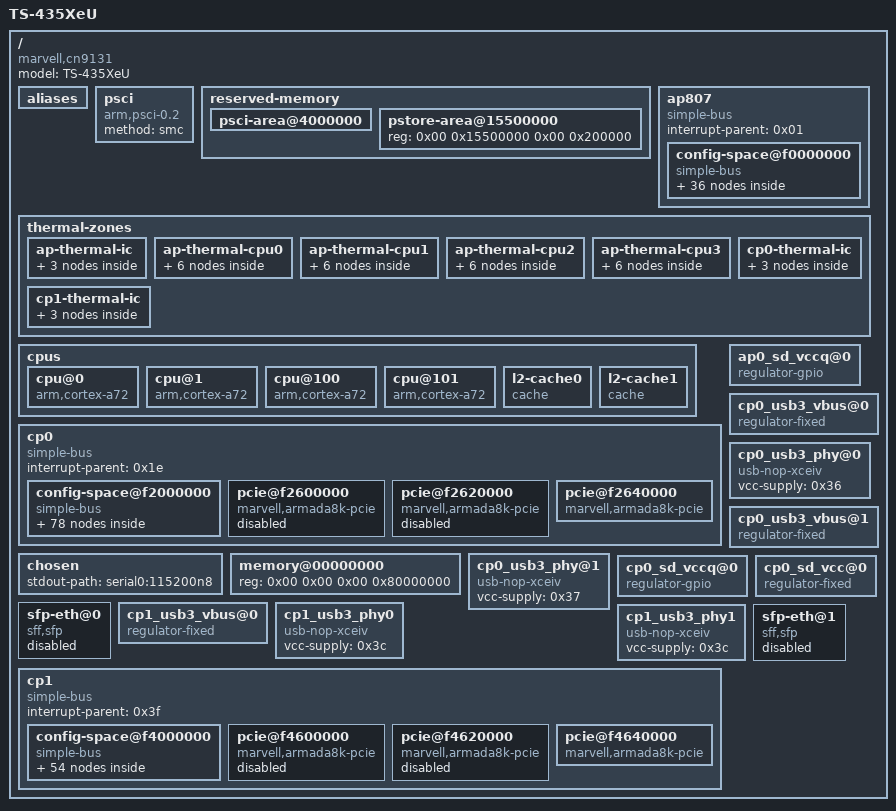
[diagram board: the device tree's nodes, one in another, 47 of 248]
/dts-v1/;

/ {
	#address-cells = <0x02>;
	#size-cells = <0x02>;
	model = "TS-435XeU";
	compatible = "marvell,cn9131\0marvell,cn9130\0marvell,armada-ap807-quad\0marvell,armada-ap807";

	aliases {
		serial0 = "/ap807/config-space@f0000000/serial@512000";
		serial1 = "/ap807/config-space@f0000000/serial@512100";
		gpio0 = "/ap807/config-space@f0000000/system-controller@6f4000/gpio@1040";
		spi0 = "/ap807/config-space@f0000000/spi@510600";
		i2c0 = "/cp0/config-space@f2000000/i2c@701000";
		ethernet0 = "/cp0/config-space@f2000000/ethernet@0/eth0";
		ethernet1 = "/cp0/config-space@f2000000/ethernet@0/eth1";
		ethernet2 = "/cp0/config-space@f2000000/ethernet@0/eth2";
		gpio1 = "/cp0/config-space@f2000000/system-controller@440000/gpio@100";
		gpio2 = "/cp0/config-space@f2000000/system-controller@440000/gpio@140";
		ethernet3 = "/cp1/config-space@f4000000/ethernet@0/eth0";
		gpio3 = "/cp1/config-space@f4000000/system-controller@440000/gpio@100";
		gpio4 = "/cp1/config-space@f4000000/system-controller@440000/gpio@140";
	};

	psci {
		compatible = "arm,psci-0.2";
		method = "smc";
	};

	reserved-memory {
		#address-cells = <0x02>;
		#size-cells = <0x02>;
		ranges;

		psci-area@4000000 {
			reg = <0x00 0x4000000 0x00 0x200000>;
			no-map;
		};

		pstore-area@15500000 {
			reg = <0x00 0x15500000 0x00 0x200000>;
		};
	};

	ap807 {
		#address-cells = <0x02>;
		#size-cells = <0x02>;
		compatible = "simple-bus";
		interrupt-parent = <0x01>;
		ranges;

		config-space@f0000000 {
			#address-cells = <0x01>;
			#size-cells = <0x01>;
			compatible = "simple-bus";
			ranges = <0x00 0x00 0xf0000000 0x1000000>;

			iommu@5000000 {
				compatible = "marvell,ap806-smmu-500\0arm,mmu-500";
				reg = <0x100000 0x100000>;
				dma-coherent;
				#iommu-cells = <0x01>;
				#global-interrupts = <0x01>;
				interrupts = <0x00 0x06 0x04 0x00 0x06 0x04 0x00 0x06 0x04 0x00 0x06 0x04 0x00 0x06 0x04 0x00 0x06 0x04 0x00 0x06 0x04 0x00 0x06 0x04 0x00 0x06 0x04>;
				status = "disabled";
				phandle = <0x05>;
			};

			interrupt-controller@210000 {
				compatible = "arm,gic-400";
				#interrupt-cells = <0x03>;
				#address-cells = <0x01>;
				#size-cells = <0x01>;
				ranges;
				interrupt-controller;
				interrupts = <0x01 0x09 0xf04>;
				reg = <0x210000 0x10000 0x220000 0x20000 0x240000 0x20000 0x260000 0x20000>;
				phandle = <0x01>;

				v2m@280000 {
					compatible = "arm,gic-v2m-frame";
					msi-controller;
					reg = <0x280000 0x1000>;
					arm,msi-base-spi = <0xa0>;
					arm,msi-num-spis = <0x20>;
					phandle = <0x03>;
				};

				v2m@290000 {
					compatible = "arm,gic-v2m-frame";
					msi-controller;
					reg = <0x290000 0x1000>;
					arm,msi-base-spi = <0xc0>;
					arm,msi-num-spis = <0x20>;
				};

				v2m@2a0000 {
					compatible = "arm,gic-v2m-frame";
					msi-controller;
					reg = <0x2a0000 0x1000>;
					arm,msi-base-spi = <0xe0>;
					arm,msi-num-spis = <0x20>;
				};

				v2m@2b0000 {
					compatible = "arm,gic-v2m-frame";
					msi-controller;
					reg = <0x2b0000 0x1000>;
					arm,msi-base-spi = <0x100>;
					arm,msi-num-spis = <0x20>;
				};
			};

			timer {
				compatible = "arm,armv8-timer";
				interrupts = <0x01 0x0d 0xf08 0x01 0x0e 0xf08 0x01 0x0b 0xf08 0x01 0x0a 0xf08>;
			};

			pmu {
				compatible = "arm,cortex-a72-pmu";
				interrupt-parent = <0x02>;
				interrupts = <0x11>;
			};

			odmi@300000 {
				compatible = "marvell,odmi-controller";
				interrupt-controller;
				msi-controller;
				marvell,odmi-frames = <0x04>;
				reg = <0x300000 0x4000 0x304000 0x4000 0x308000 0x4000 0x30c000 0x4000>;
				marvell,spi-base = <0x80 0x88 0x90 0x98>;
			};

			gicp@3f0040 {
				compatible = "marvell,ap806-gicp";
				reg = <0x3f0040 0x10>;
				marvell,spi-ranges = <0x40 0x40 0x120 0x40>;
				msi-controller;
				phandle = <0x2a>;
			};

			interrupt-controller@3f0100 {
				compatible = "marvell,armada-8k-pic";
				reg = <0x3f0100 0x10>;
				#interrupt-cells = <0x01>;
				interrupt-controller;
				interrupts = <0x01 0x0f 0x04>;
				phandle = <0x02>;
			};

			interrupt-controller@3f0200 {
				compatible = "marvell,ap806-sei";
				reg = <0x3f0200 0x40>;
				interrupts = <0x00 0x00 0x04>;
				#interrupt-cells = <0x01>;
				interrupt-controller;
				msi-controller;
				phandle = <0x0b>;
			};

			xor@400000 {
				compatible = "marvell,armada-7k-xor\0marvell,xor-v2";
				reg = <0x400000 0x1000 0x410000 0x1000>;
				msi-parent = <0x03>;
				clocks = <0x04 0x03>;
				dma-coherent;
				iommus = <0x05 0x01>;
				phandle = <0x06>;
			};

			xor@420000 {
				compatible = "marvell,armada-7k-xor\0marvell,xor-v2";
				reg = <0x420000 0x1000 0x430000 0x1000>;
				msi-parent = <0x03>;
				clocks = <0x04 0x03>;
				dma-coherent;
				iommus = <0x05 0x02>;
				phandle = <0x07>;
			};

			xor@440000 {
				compatible = "marvell,armada-7k-xor\0marvell,xor-v2";
				reg = <0x440000 0x1000 0x450000 0x1000>;
				msi-parent = <0x03>;
				clocks = <0x04 0x03>;
				dma-coherent;
				phandle = <0x08>;
			};

			xor@460000 {
				compatible = "marvell,armada-7k-xor\0marvell,xor-v2";
				reg = <0x460000 0x1000 0x470000 0x1000>;
				msi-parent = <0x03>;
				clocks = <0x04 0x03>;
				dma-coherent;
				phandle = <0x09>;
			};

			uio_xor0 {
				compatible = "marvell,uio-xor-v2";
				xor_access = <0x06>;
			};

			uio_xor1 {
				compatible = "marvell,uio-xor-v2";
				xor_access = <0x07>;
			};

			uio_xor2 {
				compatible = "marvell,uio-xor-v2";
				xor_access = <0x08>;
			};

			uio_xor3 {
				compatible = "marvell,uio-xor-v2";
				xor_access = <0x09>;
			};

			spi@510600 {
				compatible = "marvell,armada-380-spi";
				reg = <0x510600 0x50>;
				#address-cells = <0x01>;
				#size-cells = <0x00>;
				interrupts = <0x00 0x15 0x04>;
				clocks = <0x04 0x03>;
				status = "disabled";
			};

			i2c@511000 {
				compatible = "marvell,mv78230-i2c";
				reg = <0x511000 0x20>;
				#address-cells = <0x01>;
				#size-cells = <0x00>;
				interrupts = <0x00 0x14 0x04>;
				clocks = <0x04 0x03>;
				status = "disabled";
			};

			serial@512000 {
				compatible = "snps,dw-apb-uart";
				reg = <0x512000 0x100>;
				reg-shift = <0x02>;
				interrupts = <0x00 0x13 0x04>;
				reg-io-width = <0x01>;
				clocks = <0x04 0x03>;
				status = "okay";
			};

			serial@512100 {
				compatible = "snps,dw-apb-uart";
				reg = <0x512100 0x100>;
				reg-shift = <0x02>;
				interrupts = <0x00 0x1d 0x04>;
				reg-io-width = <0x01>;
				clocks = <0x04 0x03>;
				status = "disabled";
			};

			watchdog@610000 {
				compatible = "arm,sbsa-gwdt";
				reg = <0x610000 0x1000 0x600000 0x1000>;
				interrupts = <0x00 0x02 0x04>;
				timeout-sec = <0x1e>;
			};

			sdhci@6e0000 {
				compatible = "marvell,armada-ap806-sdhci";
				reg = <0x6e0000 0x300>;
				interrupts = <0x00 0x10 0x04>;
				clock-names = "core";
				clocks = <0x04 0x04>;
				dma-coherent;
				iommus = <0x05 0x05>;
				marvell,xenon-phy-slow-mode;
				status = "okay";
				pinctrl-names = "default";
				bus-width = <0x08>;
				mmc-ddr-1_8v;
				mmc-hs400-1_8v;
			};

			system-controller@6f4000 {
				compatible = "syscon\0simple-mfd";
				reg = <0x6f4000 0x2000>;

				pinctrl {
					compatible = "marvell,ap806-pinctrl";
					phandle = <0x0a>;

					uart0-pins {
						marvell,pins = "mpp11\0mpp19";
						marvell,function = "uart0";
					};
				};

				gpio@1040 {
					compatible = "marvell,armada-8k-gpio";
					offset = <0x1040>;
					ngpios = <0x14>;
					gpio-controller;
					#gpio-cells = <0x02>;
					gpio-ranges = <0x0a 0x00 0x00 0x14>;
				};

				clock {
					compatible = "marvell,ap807-clock";
					#clock-cells = <0x01>;
					phandle = <0x04>;
				};
			};

			system-controller@6f8000 {
				compatible = "syscon", "simple-mfd";
				reg = <0x6f8000 0x1000>;
				#address-cells = <0x01>;
				#size-cells = <0x01>;

				thermal-sensor@80 {
					compatible = "marvell,armada-ap807-thermal";
					reg = <0x80 0x10>;
					interrupt-parent = <0x0b>;
					interrupts = <0x12>;
					#thermal-sensor-cells = <0x01>;
					phandle = <0x0c>;
				};

				clock-cpu {
					compatible = "marvell,ap807-cpu-clock";
					clocks = <0x04 0x00 0x04 0x01>;
					#clock-cells = <0x01>;
					status = "okay";
					phandle = <0x1b>;
				};
			};

			edac-mc@20000 {
				compatible = "marvell,armada-ap80x-edac-mc";
				reg = <0x20000 0x1000>;
				interrupts = <0x00 0x05 0x04>;
				status = "okay";
			};

			musdk_cma {
				compatible = "marvell,musdk-cma";
				dma-coherent;
			};
		};
	};

	thermal-zones {

		ap-thermal-ic {
			polling-delay-passive = <0x00>;
			polling-delay = <0x00>;
			thermal-sensors = <0x0c 0x00>;

			trips {

				ap-crit {
					temperature = <0x186a0>;
					hysteresis = <0x7d0>;
					type = "critical";
				};
			};

			cooling-maps {
			};
		};

		ap-thermal-cpu0 {
			polling-delay-passive = <0x3e8>;
			polling-delay = <0x3e8>;
			thermal-sensors = <0x0c 0x01>;

			trips {

				cpu0-hot {
					temperature = <0x14c08>;
					hysteresis = <0x7d0>;
					type = "passive";
					phandle = <0x0d>;
				};

				cpu0-emerg {
					temperature = <0x17318>;
					hysteresis = <0x7d0>;
					type = "passive";
					phandle = <0x10>;
				};
			};

			cooling-maps {

				map0-hot {
					trip = <0x0d>;
					cooling-device = <0x0e 0x01 0x02 0x0f 0x01 0x02>;
				};

				map0-ermerg {
					trip = <0x10>;
					cooling-device = <0x0e 0x03 0x03 0x0f 0x03 0x03>;
				};
			};
		};

		ap-thermal-cpu1 {
			polling-delay-passive = <0x3e8>;
			polling-delay = <0x3e8>;
			thermal-sensors = <0x0c 0x02>;

			trips {

				cpu1-hot {
					temperature = <0x14c08>;
					hysteresis = <0x7d0>;
					type = "passive";
					phandle = <0x11>;
				};

				cpu1-emerg {
					temperature = <0x17318>;
					hysteresis = <0x7d0>;
					type = "passive";
					phandle = <0x12>;
				};
			};

			cooling-maps {

				map1-hot {
					trip = <0x11>;
					cooling-device = <0x0e 0x01 0x02 0x0f 0x01 0x02>;
				};

				map1-emerg {
					trip = <0x12>;
					cooling-device = <0x0e 0x03 0x03 0x0f 0x03 0x03>;
				};
			};
		};

		ap-thermal-cpu2 {
			polling-delay-passive = <0x3e8>;
			polling-delay = <0x3e8>;
			thermal-sensors = <0x0c 0x03>;

			trips {

				cpu2-hot {
					temperature = <0x14c08>;
					hysteresis = <0x7d0>;
					type = "passive";
					phandle = <0x13>;
				};

				cpu2-emerg {
					temperature = <0x17318>;
					hysteresis = <0x7d0>;
					type = "passive";
					phandle = <0x16>;
				};
			};

			cooling-maps {

				map2-hot {
					trip = <0x13>;
					cooling-device = <0x14 0x01 0x02 0x15 0x01 0x02>;
				};

				map2-emerg {
					trip = <0x16>;
					cooling-device = <0x14 0x03 0x03 0x15 0x03 0x03>;
				};
			};
		};

		ap-thermal-cpu3 {
			polling-delay-passive = <0x3e8>;
			polling-delay = <0x3e8>;
			thermal-sensors = <0x0c 0x04>;

			trips {

				cpu3-hot {
					temperature = <0x14c08>;
					hysteresis = <0x7d0>;
					type = "passive";
					phandle = <0x17>;
				};

				cpu3-emerg {
					temperature = <0x17318>;
					hysteresis = <0x7d0>;
					type = "passive";
					phandle = <0x18>;
				};
			};

			cooling-maps {

				map3-bhot {
					trip = <0x17>;
					cooling-device = <0x14 0x01 0x02 0x15 0x01 0x02>;
				};

				map3-emerg {
					trip = <0x18>;
					cooling-device = <0x14 0x03 0x03 0x15 0x03 0x03>;
				};
			};
		};

		cp0-thermal-ic {
			polling-delay-passive = <0x00>;
			polling-delay = <0x00>;
			thermal-sensors = <0x19 0x00>;

			trips {

				crit {
					temperature = <0x186a0>;
					hysteresis = <0x7d0>;
					type = "critical";
				};
			};

			cooling-maps {
			};
		};

		cp1-thermal-ic {
			polling-delay-passive = <0x00>;
			polling-delay = <0x00>;
			thermal-sensors = <0x1a 0x00>;

			trips {

				crit {
					temperature = <0x186a0>;
					hysteresis = <0x7d0>;
					type = "critical";
				};
			};

			cooling-maps {
			};
		};
	};

	cpus {
		#address-cells = <0x01>;
		#size-cells = <0x00>;

		cpu@0 {
			device_type = "cpu";
			compatible = "arm,cortex-a72";
			reg = <0x00>;
			enable-method = "psci";
			#cooling-cells = <0x02>;
			clocks = <0x1b 0x00>;
			i-cache-size = <0xc000>;
			i-cache-line-size = <0x40>;
			i-cache-sets = <0x100>;
			d-cache-size = <0x8000>;
			d-cache-line-size = <0x40>;
			d-cache-sets = <0x100>;
			next-level-cache = <0x1c>;
			phandle = <0x0e>;
		};

		cpu@1 {
			device_type = "cpu";
			compatible = "arm,cortex-a72";
			reg = <0x01>;
			enable-method = "psci";
			#cooling-cells = <0x02>;
			clocks = <0x1b 0x00>;
			i-cache-size = <0xc000>;
			i-cache-line-size = <0x40>;
			i-cache-sets = <0x100>;
			d-cache-size = <0x8000>;
			d-cache-line-size = <0x40>;
			d-cache-sets = <0x100>;
			next-level-cache = <0x1c>;
			phandle = <0x0f>;
		};

		cpu@100 {
			device_type = "cpu";
			compatible = "arm,cortex-a72";
			reg = <0x100>;
			enable-method = "psci";
			#cooling-cells = <0x02>;
			clocks = <0x1b 0x01>;
			i-cache-size = <0xc000>;
			i-cache-line-size = <0x40>;
			i-cache-sets = <0x100>;
			d-cache-size = <0x8000>;
			d-cache-line-size = <0x40>;
			d-cache-sets = <0x100>;
			next-level-cache = <0x1d>;
			phandle = <0x14>;
		};

		cpu@101 {
			device_type = "cpu";
			compatible = "arm,cortex-a72";
			reg = <0x101>;
			enable-method = "psci";
			#cooling-cells = <0x02>;
			clocks = <0x1b 0x01>;
			i-cache-size = <0xc000>;
			i-cache-line-size = <0x40>;
			i-cache-sets = <0x100>;
			d-cache-size = <0x8000>;
			d-cache-line-size = <0x40>;
			d-cache-sets = <0x100>;
			next-level-cache = <0x1d>;
			phandle = <0x15>;
		};

		l2-cache0 {
			compatible = "cache";
			cache-size = <0x80000>;
			cache-line-size = <0x40>;
			cache-sets = <0x200>;
			phandle = <0x1c>;
		};

		l2-cache1 {
			compatible = "cache";
			cache-size = <0x80000>;
			cache-line-size = <0x40>;
			cache-sets = <0x200>;
			phandle = <0x1d>;
		};
	};

	cp0 {
		#address-cells = <0x02>;
		#size-cells = <0x02>;
		compatible = "simple-bus";
		interrupt-parent = <0x1e>;
		ranges;

		config-space@f2000000 {
			#address-cells = <0x01>;
			#size-cells = <0x01>;
			compatible = "simple-bus";
			ranges = <0x00 0x00 0xf2000000 0x2000000>;

			ethernet@0 {
				compatible = "marvell,armada-7k-pp22";
				reg = <0x00 0x100000 0x129000 0xb000>;
				clocks = <0x1f 0x01 0x03 0x1f 0x01 0x09 0x1f 0x01 0x05 0x1f 0x01 0x06 0x1f 0x01 0x12>;
				clock-names = "pp_clk\0gop_clk\0mg_clk\0mg_core_clk\0axi_clk";
				marvell,system-controller = <0x20>;
				status = "okay";
				dma-coherent;
				cm3-mem = <0x21>;

				eth0 {
					interrupts = <0x27 0x04 0x2b 0x04 0x2f 0x04 0x33 0x04 0x37 0x04 0x3b 0x04 0x3f 0x04 0x43 0x04 0x47 0x04 0x81 0x04>;
					interrupt-names = "hif0\0hif1\0hif2\0hif3\0hif4\0hif5\0hif6\0hif7\0hif8\0link";
					port-id = <0x00>;
					gop-port-id = <0x00>;
					status = "okay";
					phy-mode = "10gbase-r";
					phys = <0x22 0x00>;
					managed = "in-band-status";
					sfp = <0x23>;
					led-active = <0x5c 0x01>;
					led-link-10G = <0x5d 0x01>;
					led-link-1G = <0x5e 0x01>;
				};

				eth1 {
					interrupts = <0x28 0x04 0x2c 0x04 0x30 0x04 0x34 0x04 0x38 0x04 0x3c 0x04 0x40 0x04 0x44 0x04 0x48 0x04 0x80 0x04>;
					interrupt-names = "hif0\0hif1\0hif2\0hif3\0hif4\0hif5\0hif6\0hif7\0hif8\0link";
					reg = <0x01>;
					port-id = <0x01>;
					gop-port-id = <0x02>;
					status = "okay";
					phy-mode = "2500base-x";
					phy = <0x25>;
				};

				eth2 {
					interrupts = <0x29 0x04 0x2d 0x04 0x31 0x04 0x35 0x04 0x39 0x04 0x3d 0x04 0x41 0x04 0x45 0x04 0x49 0x04 0x7f 0x04>;
					interrupt-names = "hif0\0hif1\0hif2\0hif3\0hif4\0hif5\0hif6\0hif7\0hif8\0link";
					reg = <0x02>;
					port-id = <0x02>;
					gop-port-id = <0x03>;
					status = "okay";
					phy-mode = "2500base-x";
					phy = <0x27>;
				};
			};

			uio_pp_0@0 {
				compatible = "generic-uio";
				reg = <0x00 0x90000 0x130000 0x6000 0x220000 0x1000>;
				reg-names = "pp\0mspg\0cm3";
			};

			qnap_comphy_init {
				compatible = "qnap,comphy-cp110";
				reg-map = <0x120000 0x6000>;
				status = "okay";
				comphy_settings = <0xf2122844 0x4958 0xf2122c50 0xf0fe 0xf212283c 0x4958 0xf2122834 0x4958 0xf2124834 0x49d6 0xf2124c40 0xf2ef>;
			};

			phy@120000 {
				compatible = "marvell,comphy-cp110";
				reg = <0x120000 0x6000>;
				marvell,system-controller = <0x20>;
				clocks = <0x1f 0x01 0x05 0x1f 0x01 0x06 0x1f 0x01 0x12>;
				clock-names = "mg_clk\0mg_core_clk\0axi_clk";
				#address-cells = <0x01>;
				#size-cells = <0x00>;

				phy@0 {
					reg = <0x00>;
					#phy-cells = <0x01>;
					phandle = <0x2e>;
				};

				phy@1 {
					reg = <0x01>;
					#phy-cells = <0x01>;
					phandle = <0x26>;
				};

				phy@2 {
					reg = <0x02>;
					#phy-cells = <0x01>;
					phandle = <0x2d>;
				};

				phy@3 {
					reg = <0x03>;
					#phy-cells = <0x01>;
					phandle = <0x24>;
				};

				phy@4 {
					reg = <0x04>;
					#phy-cells = <0x01>;
					phandle = <0x22>;
				};

				phy@5 {
					reg = <0x05>;
					#phy-cells = <0x01>;
					phandle = <0x34>;
				};
			};

			mdio@12a200 {
				#address-cells = <0x01>;
				#size-cells = <0x00>;
				compatible = "marvell,orion-mdio";
				reg = <0x12a200 0x10>;
				clocks = <0x1f 0x01 0x09 0x1f 0x01 0x05 0x1f 0x01 0x06 0x1f 0x01 0x12>;
				status = "disabled";
				phandle = <0x28>;
			};

			mdio@12a600 {
				#address-cells = <0x01>;
				#size-cells = <0x00>;
				compatible = "marvell,xmdio";
				reg = <0x12a600 0x10>;
				clocks = <0x1f 0x01 0x05 0x1f 0x01 0x06 0x1f 0x01 0x12>;
				status = "okay";
				phandle = <0x29>;

				ethernet-phy@0 {
					compatible = "ethernet-phy-ieee802.3-c45";
					reg = <0x00>;
					phandle = <0x25>;
				};

				ethernet-phy@1 {
					compatible = "ethernet-phy-ieee802.3-c45";
					reg = <0x08>;
					phandle = <0x27>;
				};
			};

			mdio_uio {
				compatible = "marvell,mvmdio-uio";
				mii-bus = <0x28>;
				status = "disabled";
			};

			xmdio_uio {
				compatible = "marvell,mvmdio-uio";
				mii-bus = <0x29>;
				status = "okay";
			};

			interrupt-controller@1e0000 {
				compatible = "marvell,cp110-icu";
				reg = <0x1e0000 0x440>;
				#address-cells = <0x01>;
				#size-cells = <0x01>;

				interrupt-controller@10 {
					compatible = "marvell,cp110-icu-nsr";
					reg = <0x10 0x20>;
					#interrupt-cells = <0x02>;
					interrupt-controller;
					msi-parent = <0x2a>;
					phandle = <0x1e>;
				};

				interrupt-controller@50 {
					compatible = "marvell,cp110-icu-sei";
					reg = <0x50 0x10>;
					#interrupt-cells = <0x02>;
					interrupt-controller;
					msi-parent = <0x0b>;
					phandle = <0x2c>;
				};
			};

			cm3@220000 {
				compatible = "mmio-sram";
				reg = <0x220000 0x800>;
				#address-cells = <0x01>;
				#size-cells = <0x01>;
				ranges = <0x00 0x220000 0x800>;
				phandle = <0x21>;
			};

			rtc@284000 {
				compatible = "marvell,armada-8k-rtc";
				reg = <0x284000 0x20 0x284080 0x24>;
				reg-names = "rtc\0rtc-soc";
				interrupts = <0x4d 0x04>;
				status = "disabled";
			};

			system-controller@440000 {
				compatible = "syscon\0simple-mfd";
				reg = <0x440000 0x2000>;
				phandle = <0x20>;

				clock {
					compatible = "marvell,cp110-clock";
					#clock-cells = <0x02>;
					phandle = <0x1f>;
				};

				gpio@100 {
					compatible = "marvell,armada-8k-gpio";
					offset = <0x100>;
					ngpios = <0x20>;
					gpio-controller;
					#gpio-cells = <0x02>;
					gpio-ranges = <0x2b 0x00 0x00 0x20>;
					interrupt-controller;
					interrupts = <0x56 0x04 0x55 0x04 0x54 0x04 0x53 0x04>;
					#interrupt-cells = <0x02>;
					status = "okay";
				};

				gpio@140 {
					compatible = "marvell,armada-8k-gpio";
					offset = <0x140>;
					ngpios = <0x1f>;
					gpio-controller;
					#gpio-cells = <0x02>;
					gpio-ranges = <0x2b 0x00 0x20 0x1f>;
					interrupt-controller;
					interrupts = <0x52 0x04 0x51 0x04 0x50 0x04 0x4f 0x04>;
					#interrupt-cells = <0x02>;
					status = "okay";
				};

				pinctrl {
					compatible = "marvell,cp115-standalone-pinctrl";
					phandle = <0x2b>;

					cp0-i2c-pins-0 {
						marvell,pins = "mpp37\0mpp38";
						marvell,function = "i2c0";
						phandle = <0x32>;
					};

					cp0-i2c-pins-1 {
						marvell,pins = "mpp35\0mpp36";
						marvell,function = "i2c1";
					};

					cp0-ge-rgmii-pins-0 {
						marvell,pins = "mpp0\0mpp1\0mpp2\0mpp3\0mpp4\0mpp5\0mpp6\0mpp7\0mpp8\0mpp9\0mpp10\0mpp11";
						marvell,function = "ge0";
					};

					cp0-ge-rgmii-pins-1 {
						marvell,pins = "mpp44\0mpp45\0mpp46\0mpp47\0mpp48\0mpp49\0mpp50\0mpp51\0mpp52\0mpp53\0mpp54\0mpp55";
						marvell,function = "ge1";
					};

					cp0-sdhci-cd-pins-0 {
						marvell,pins = "mpp43";
						marvell,function = "gpio";
					};

					cp0-sdhi-pins-0 {
						marvell,pins = "mpp56\0mpp57\0mpp58\0mpp59\0mpp60\0mpp61";
						marvell,function = "sdio";
					};

					cp0-spi-pins-0 {
						marvell,pins = "mpp13\0mpp14\0mpp15\0mpp16";
						marvell,function = "spi1";
						phandle = <0x31>;
					};

					nand-pins {
						marvell,pins = "mpp15\0mpp16\0mpp17\0mpp18\0mpp19\0mpp20\0mpp21\0mpp22\0mpp23\0mpp24\0mpp25\0mpp26\0mpp27";
						marvell,function = "dev";
					};

					nand-rb {
						marvell,pins = "mpp13";
						marvell,function = "nf";
					};
				};
			};

			system-controller@400000 {
				compatible = "syscon\0simple-mfd";
				reg = <0x400000 0x1000>;
				#address-cells = <0x01>;
				#size-cells = <0x01>;

				thermal-sensor@70 {
					compatible = "marvell,armada-cp110-thermal";
					reg = <0x70 0x10>;
					interrupts-extended = <0x2c 0x74 0x04>;
					#thermal-sensor-cells = <0x01>;
					phandle = <0x19>;
				};
			};

			usb3@500000 {
				compatible = "marvell,armada-8k-xhci\0generic-xhci";
				reg = <0x500000 0x4000>;
				dma-coherent;
				interrupts = <0x6a 0x04>;
				clock-names = "core\0reg";
				clocks = <0x1f 0x01 0x16 0x1f 0x01 0x10>;
				status = "okay";
				iommus = <0x05 0x440>;
			};

			usb3@510000 {
				compatible = "marvell,armada-8k-xhci\0generic-xhci";
				reg = <0x510000 0x4000>;
				dma-coherent;
				interrupts = <0x69 0x04>;
				clock-names = "core\0reg";
				clocks = <0x1f 0x01 0x17 0x1f 0x01 0x10>;
				status = "okay";
				iommus = <0x05 0x441>;
			};

			sata@540000 {
				compatible = "marvell,armada-8k-ahci\0generic-ahci";
				reg = <0x540000 0x30000>;
				dma-coherent;
				interrupts = <0x6b 0x04>;
				clocks = <0x1f 0x01 0x0f 0x1f 0x01 0x10>;
				#address-cells = <0x01>;
				#size-cells = <0x00>;
				status = "okay";
				iommus = <0x05 0x444>;

				sata-port@0 {
					reg = <0x00>;
					status = "okay";
					phys = <0x2d 0x00>;
				};

				sata-port@1 {
					reg = <0x01>;
					status = "okay";
					phys = <0x2e 0x01>;
				};
			};

			xor@6a0000 {
				compatible = "marvell,armada-7k-xor\0marvell,xor-v2";
				reg = <0x6a0000 0x1000 0x6b0000 0x1000>;
				dma-coherent;
				msi-parent = <0x03>;
				clock-names = "core\0reg";
				clocks = <0x1f 0x01 0x08 0x1f 0x01 0x0e>;
				phandle = <0x2f>;
			};

			xor@6c0000 {
				compatible = "marvell,armada-7k-xor\0marvell,xor-v2";
				reg = <0x6c0000 0x1000 0x6d0000 0x1000>;
				dma-coherent;
				msi-parent = <0x03>;
				clock-names = "core\0reg";
				clocks = <0x1f 0x01 0x07 0x1f 0x01 0x0e>;
				phandle = <0x30>;
			};

			cp0_uio_xor0 {
				compatible = "marvell,uio-xor-v2";
				xor_access = <0x2f>;
			};

			cp0_uio_xor1 {
				compatible = "marvell,uio-xor-v2";
				xor_access = <0x30>;
			};

			spi@700600 {
				compatible = "marvell,armada-380-spi";
				reg = <0x700600 0x50>;
				#address-cells = <0x01>;
				#size-cells = <0x00>;
				clock-names = "core\0axi";
				clocks = <0x1f 0x01 0x15 0x1f 0x01 0x11>;
				status = "okay";
			};

			spi@700680 {
				compatible = "marvell,armada-380-spi";
				reg = <0x700680 0x50 0x2000000 0x1000000>;
				#address-cells = <0x01>;
				#size-cells = <0x00>;
				clock-names = "core\0axi";
				clocks = <0x1f 0x01 0x15 0x1f 0x01 0x11>;
				status = "okay";
				pinctrl-names = "default";
				pinctrl-0 = <0x31>;

				spi-flash@0 {
					#address-cells = <0x01>;
					#size-cells = <0x01>;
					compatible = "jedec,spi-nor";
					reg = <0x00>;
					spi-max-frequency = <0x2625a00>;

					partitions {
						compatible = "fixed-partitions";
						#address-cells = <0x01>;
						#size-cells = <0x01>;

						partition@0 {
							label = "U-Boot";
							reg = <0x00 0x3e0000>;
						};

						partition@3F0000 {
							label = "U-boot Env";
							reg = <0x3f0000 0x10000>;
						};

						partition@400000 {
							label = "ALL partition";
							reg = <0x00 0x400000>;
						};
					};
				};
			};

			i2c0: i2c@701000 {
				compatible = "marvell,mv78230-i2c";
				reg = <0x701000 0x20>;
				#address-cells = <0x01>;
				#size-cells = <0x00>;
				interrupts = <0x78 0x04>;
				clock-names = "core\0reg";
				clocks = <0x1f 0x01 0x15 0x1f 0x01 0x11>;
				status = "okay";
				pinctrl-names = "default";
				pinctrl-0 = <0x32>;
				clock-frequency = <0x186a0>;

				pca953x@21 {
					compatible = "nxp,pca9555";
					pinctrl-names = "default";
					gpio-controller;
					#gpio-cells = <0x02>;
					reg = <0x21>;
					status = "okay";
					phandle = <0x35>;
				};

				rtc@32 {
					compatible = "epson,rx8130";
					status = "okay";
					reg = <0x32>;
					wakeup-source;
					trickle-diode-disable;
				};

				eeprom@50 {
					compatible = "atmel,24c64";
					reg = <0x50>;
					pagesize = <0x20>;
				};

				eeprom@57 {
					compatible = "atmel,24c64";
					reg = <0x57>;
					pagesize = <0x20>;
				};
			};

			i2c@701100 {
				compatible = "marvell,mv78230-i2c";
				reg = <0x701100 0x20>;
				#address-cells = <0x01>;
				#size-cells = <0x00>;
				interrupts = <0x79 0x04>;
				clock-names = "core\0reg";
				clocks = <0x1f 0x01 0x15 0x1f 0x01 0x11>;
				status = "disabled";
				clock-frequency = <0x186a0>;

				i2c-mux@72 {
					compatible = "nxp,pca9544";
					#address-cells = <0x01>;
					#size-cells = <0x00>;
					reg = <0x72>;

					i2c@0 {
						#address-cells = <0x01>;
						#size-cells = <0x00>;
						reg = <0x00>;
						phandle = <0x38>;
					};

					i2c@1 {
						#address-cells = <0x01>;
						#size-cells = <0x00>;
						reg = <0x01>;

						pca9555@21 {
							compatible = "nxp,pca9555";
							pinctrl-names = "default";
							gpio-controller;
							#gpio-cells = <0x02>;
							reg = <0x21>;
							phandle = <0x39>;
						};
					};
				};
			};

			cp0_uart0: serial@702000 {
				compatible = "snps,dw-apb-uart";
				reg = <0x702000 0x100>;
				reg-shift = <0x02>;
				interrupts = <0x7a 0x04>;
				reg-io-width = <0x01>;
				clock-names = "baudclk\0apb_pclk";
				clocks = <0x1f 0x01 0x15 0x1f 0x01 0x11>;
				status = "okay";
			};

			serial@702100 {
				compatible = "snps,dw-apb-uart";
				reg = <0x702100 0x100>;
				reg-shift = <0x02>;
				interrupts = <0x7b 0x04>;
				reg-io-width = <0x01>;
				clock-names = "baudclk\0apb_pclk";
				clocks = <0x1f 0x01 0x15 0x1f 0x01 0x11>;
				status = "disabled";
			};

			serial@702200 {
				compatible = "snps,dw-apb-uart";
				reg = <0x702200 0x100>;
				reg-shift = <0x02>;
				interrupts = <0x7c 0x04>;
				reg-io-width = <0x01>;
				clock-names = "baudclk\0apb_pclk";
				clocks = <0x1f 0x01 0x15 0x1f 0x01 0x11>;
				status = "disabled";
			};

			serial@702300 {
				compatible = "snps,dw-apb-uart";
				reg = <0x702300 0x100>;
				reg-shift = <0x02>;
				interrupts = <0x7d 0x04>;
				reg-io-width = <0x01>;
				clock-names = "baudclk\0apb_pclk";
				clocks = <0x1f 0x01 0x15 0x1f 0x01 0x11>;
				status = "disabled";
			};

			nand@720000 {
				compatible = "marvell,armada-8k-nand-controller\0marvell,armada370-nand-controller";
				reg = <0x720000 0x54>;
				#address-cells = <0x01>;
				#size-cells = <0x00>;
				interrupts = <0x73 0x04>;
				clock-names = "core\0reg";
				clocks = <0x1f 0x01 0x02 0x1f 0x01 0x11>;
				marvell,system-controller = <0x20>;
				status = "disabled";
			};

			trng@760000 {
				compatible = "marvell,armada-8k-rng\0inside-secure,safexcel-eip76";
				reg = <0x760000 0x7d>;
				interrupts = <0x5f 0x04>;
				clock-names = "core\0reg";
				clocks = <0x1f 0x01 0x19 0x1f 0x01 0x11>;
				status = "okay";
			};

			sdhci@780000 {
				compatible = "marvell,armada-cp110-sdhci";
				reg = <0x780000 0x300>;
				interrupts = <0x1b 0x04>;
				clock-names = "core\0axi";
				clocks = <0x1f 0x01 0x04 0x1f 0x01 0x12>;
				dma-coherent;
				status = "disabled";
				iommus = <0x05 0x445>;
			};

			crypto@800000 {
				compatible = "inside-secure,safexcel-eip197b";
				reg = <0x800000 0x200000>;
				interrupts = <0x57 0x04 0x58 0x04 0x59 0x04 0x5a 0x04 0x5b 0x04 0x5c 0x04>;
				interrupt-names = "mem\0ring0\0ring1\0ring2\0ring3\0eip";
				clock-names = "core\0reg";
				clocks = <0x1f 0x01 0x1a 0x1f 0x01 0x11>;
				dma-coherent;
				status = "okay";
				phandle = <0x33>;
			};

			uio_sam@800000 {
				compatible = "marvell,uio-sam";
				eip_access = <0x33>;
			};
		};

		pcie@f2600000 {
			compatible = "marvell,armada8k-pcie\0snps,dw-pcie";
			reg = <0x00 0xf2600000 0x00 0x10000 0x00 0xdff00000 0x00 0x80000>;
			reg-names = "ctrl\0config";
			#address-cells = <0x03>;
			#size-cells = <0x02>;
			#interrupt-cells = <0x01>;
			device_type = "pci";
			dma-coherent;
			msi-parent = <0x03>;
			bus-range = <0x00 0xff>;
			ranges = <0x82000000 0x00 0xc0000000 0x00 0xc0000000 0x00 0x1ff00000>;
			interrupt-map-mask = <0x00 0x00 0x00 0x00>;
			interrupt-map = <0x00 0x00 0x00 0x00 0x1e 0x16 0x04>;
			interrupts = <0x16 0x04>;
			num-lanes = <0x01>;
			clock-names = "core\0reg";
			clocks = <0x1f 0x01 0x0d 0x1f 0x01 0x0e>;
			status = "disabled";
		};

		pcie@f2620000 {
			compatible = "marvell,armada8k-pcie\0snps,dw-pcie";
			reg = <0x00 0xf2620000 0x00 0x10000 0x00 0xe0f00000 0x00 0x80000>;
			reg-names = "ctrl\0config";
			#address-cells = <0x03>;
			#size-cells = <0x02>;
			#interrupt-cells = <0x01>;
			device_type = "pci";
			dma-coherent;
			msi-parent = <0x03>;
			bus-range = <0x00 0xff>;
			ranges = <0x82000000 0x00 0xe0000000 0x00 0xe0000000 0x00 0xf00000>;
			interrupt-map-mask = <0x00 0x00 0x00 0x00>;
			interrupt-map = <0x00 0x00 0x00 0x00 0x1e 0x18 0x04>;
			interrupts = <0x18 0x04>;
			num-lanes = <0x01>;
			clock-names = "core\0reg";
			clocks = <0x1f 0x01 0x0b 0x1f 0x01 0x0e>;
			status = "disabled";
		};

		pcie@f2640000 {
			compatible = "marvell,armada8k-pcie\0snps,dw-pcie";
			reg = <0x00 0xf2640000 0x00 0x10000 0x00 0xe1f00000 0x00 0x80000>;
			reg-names = "ctrl\0config";
			#address-cells = <0x03>;
			#size-cells = <0x02>;
			#interrupt-cells = <0x01>;
			device_type = "pci";
			dma-coherent;
			msi-parent = <0x03>;
			bus-range = <0x00 0xff>;
			ranges = <0x82000000 0x00 0xe1000000 0x00 0xe1000000 0x00 0xf00000>;
			interrupt-map-mask = <0x00 0x00 0x00 0x00>;
			interrupt-map = <0x00 0x00 0x00 0x00 0x1e 0x17 0x04>;
			interrupts = <0x17 0x04>;
			num-lanes = <0x01>;
			clock-names = "core\0reg";
			clocks = <0x1f 0x01 0x0c 0x1f 0x01 0x0e>;
			status = "okay";
			num-viewport = <0x08>;
			phys = <0x34 0x02>;
		};
	};

	chosen {
		stdout-path = "serial0:115200n8";
	};

	memory@00000000 {
		device_type = "memory";
		reg = <0x00 0x00 0x00 0x80000000>;
	};

	ap0_sd_vccq@0 {
		compatible = "regulator-gpio";
		regulator-name = "ap0_sd_vccq";
		regulator-min-microvolt = <0x1b7740>;
		regulator-max-microvolt = <0x325aa0>;
		gpios = <0x35 0x08 0x00>;
		states = <0x1b7740 0x01 0x325aa0 0x00>;
	};

	cp0_usb3_vbus@0 {
		compatible = "regulator-fixed";
		regulator-name = "cp0-xhci0-vbus";
		regulator-min-microvolt = <0x4c4b40>;
		regulator-max-microvolt = <0x4c4b40>;
		enable-active-high;
		gpio = <0x35 0x00 0x00>;
		phandle = <0x36>;
	};

	cp0_usb3_phy@0 {
		compatible = "usb-nop-xceiv";
		vcc-supply = <0x36>;
	};

	cp0_usb3_vbus@1 {
		compatible = "regulator-fixed";
		regulator-name = "cp0-xhci1-vbus";
		regulator-min-microvolt = <0x4c4b40>;
		regulator-max-microvolt = <0x4c4b40>;
		enable-active-high;
		gpio = <0x35 0x01 0x00>;
		phandle = <0x37>;
	};

	cp0_usb3_phy@1 {
		compatible = "usb-nop-xceiv";
		vcc-supply = <0x37>;
	};

	cp0_sd_vccq@0 {
		compatible = "regulator-gpio";
		regulator-name = "cp0_sd_vccq";
		regulator-min-microvolt = <0x1b7740>;
		regulator-max-microvolt = <0x325aa0>;
		gpios = <0x35 0x0f 0x00>;
		states = <0x1b7740 0x01 0x325aa0 0x00>;
	};

	cp0_sd_vcc@0 {
		compatible = "regulator-fixed";
		regulator-name = "cp0_sd_vcc";
		regulator-min-microvolt = <0x325aa0>;
		regulator-max-microvolt = <0x325aa0>;
		gpio = <0x35 0x0e 0x00>;
		enable-active-high;
		regulator-always-on;
	};

	sfp-eth@0 {
		compatible = "sff,sfp";
		i2c-bus = <0x38>;
		los-gpio = <0x39 0x0b 0x00>;
		mod-def0-gpio = <0x39 0x0a 0x01>;
		tx-disable-gpio = <0x39 0x09 0x00>;
		tx-fault-gpio = <0x39 0x08 0x00>;
		status = "disabled";
		phandle = <0x23>;
	};

	cp1_usb3_vbus@0 {
		compatible = "regulator-fixed";
		pinctrl-names = "default";
		pinctrl-0 = <0x3a>;
		regulator-name = "cp1-xhci0-vbus";
		regulator-min-microvolt = <0x4c4b40>;
		regulator-max-microvolt = <0x4c4b40>;
		enable-active-high;
		gpio = <0x3b 0x03 0x00>;
		phandle = <0x3c>;
	};

	cp1_usb3_phy0 {
		compatible = "usb-nop-xceiv";
		vcc-supply = <0x3c>;
		phandle = <0x49>;
	};

	cp1_usb3_phy1 {
		compatible = "usb-nop-xceiv";
		vcc-supply = <0x3c>;
		phandle = <0x4b>;
	};

	sfp-eth@1 {
		compatible = "sff,sfp";
		i2c-bus = <0x3d>;
		los-gpio = <0x3b 0x0b 0x00>;
		mod-def0-gpio = <0x3b 0x0a 0x01>;
		tx-disable-gpio = <0x3b 0x09 0x00>;
		tx-fault-gpio = <0x3b 0x08 0x00>;
		pinctrl-names = "default";
		pinctrl-0 = <0x3e>;
		status = "disabled";
		phandle = <0x44>;
	};

	cp1 {
		#address-cells = <0x02>;
		#size-cells = <0x02>;
		compatible = "simple-bus";
		interrupt-parent = <0x3f>;
		ranges;

		config-space@f4000000 {
			#address-cells = <0x01>;
			#size-cells = <0x01>;
			compatible = "simple-bus";
			ranges = <0x00 0x00 0xf4000000 0x2000000>;

			ethernet@0 {
				compatible = "marvell,armada-7k-pp22";
				reg = <0x00 0x100000 0x129000 0xb000>;
				clocks = <0x40 0x01 0x03 0x40 0x01 0x09 0x40 0x01 0x05 0x40 0x01 0x06 0x40 0x01 0x12>;
				clock-names = "pp_clk\0gop_clk\0mg_clk\0mg_core_clk\0axi_clk";
				marvell,system-controller = <0x41>;
				status = "okay";
				dma-coherent;
				cm3-mem = <0x42>;

				eth0 {
					interrupts = <0x27 0x04 0x2b 0x04 0x2f 0x04 0x33 0x04 0x37 0x04 0x3b 0x04 0x3f 0x04 0x43 0x04 0x47 0x04 0x81 0x04>;
					interrupt-names = "hif0\0hif1\0hif2\0hif3\0hif4\0hif5\0hif6\0hif7\0hif8\0link";
					port-id = <0x00>;
					gop-port-id = <0x00>;
					status = "okay";
					phy-mode = "10gbase-r";
					phys = <0x43 0x00>;
					managed = "in-band-status";
					sfp = <0x44>;
					led-active = <0x9c 0x01>;
					led-link-10G = <0x9d 0x01>;
					led-link-1G = <0x9e 0x01>;
				};

				eth1 {
					interrupts = <0x28 0x04 0x2c 0x04 0x30 0x04 0x34 0x04 0x38 0x04 0x3c 0x04 0x40 0x04 0x44 0x04 0x48 0x04 0x80 0x04>;
					interrupt-names = "hif0\0hif1\0hif2\0hif3\0hif4\0hif5\0hif6\0hif7\0hif8\0link";
					port-id = <0x01>;
					gop-port-id = <0x02>;
					status = "disabled";
				};

				eth2 {
					interrupts = <0x29 0x04 0x2d 0x04 0x31 0x04 0x35 0x04 0x39 0x04 0x3d 0x04 0x41 0x04 0x45 0x04 0x49 0x04 0x7f 0x04>;
					interrupt-names = "hif0\0hif1\0hif2\0hif3\0hif4\0hif5\0hif6\0hif7\0hif8\0link";
					port-id = <0x02>;
					gop-port-id = <0x03>;
					status = "disabled";
				};
			};

			uio_pp_1@0 {
				compatible = "generic-uio";
				reg = <0x00 0x90000 0x130000 0x6000 0x220000 0x1000>;
				reg-names = "pp\0mspg\0cm3";
			};

			qnap_comphy_init {
				compatible = "qnap,comphy-cp110";
				reg-map = <0x120000 0x6000>;
				status = "okay";
				comphy_settings = <0xf4122844 0x4958 0xf4122c50 0xf0fe 0xf412283c 0x4958 0xf4122834 0x4958 0xf4124834 0x494e 0xf4124c40 0xf2ff>;
			};

			phy@120000 {
				compatible = "marvell,comphy-cp110";
				reg = <0x120000 0x6000>;
				marvell,system-controller = <0x41>;
				clocks = <0x40 0x01 0x05 0x40 0x01 0x06 0x40 0x01 0x12>;
				clock-names = "mg_clk\0mg_core_clk\0axi_clk";
				#address-cells = <0x01>;
				#size-cells = <0x00>;

				phy@0 {
					reg = <0x00>;
					#phy-cells = <0x01>;
					phandle = <0x4e>;
				};

				phy@1 {
					reg = <0x01>;
					#phy-cells = <0x01>;
					phandle = <0x4a>;
				};

				phy@2 {
					reg = <0x02>;
					#phy-cells = <0x01>;
					phandle = <0x4d>;
				};

				phy@3 {
					reg = <0x03>;
					#phy-cells = <0x01>;
					phandle = <0x4c>;
				};

				phy@4 {
					reg = <0x04>;
					#phy-cells = <0x01>;
					phandle = <0x43>;
				};

				phy@5 {
					reg = <0x05>;
					#phy-cells = <0x01>;
					phandle = <0x52>;
				};
			};

			mdio@12a200 {
				#address-cells = <0x01>;
				#size-cells = <0x00>;
				compatible = "marvell,orion-mdio";
				reg = <0x12a200 0x10>;
				clocks = <0x40 0x01 0x09 0x40 0x01 0x05 0x40 0x01 0x06 0x40 0x01 0x12>;
				status = "disabled";
				phandle = <0x45>;
			};

			mdio@12a600 {
				#address-cells = <0x01>;
				#size-cells = <0x00>;
				compatible = "marvell,xmdio";
				reg = <0x12a600 0x10>;
				clocks = <0x40 0x01 0x05 0x40 0x01 0x06 0x40 0x01 0x12>;
				status = "disabled";
				phandle = <0x46>;
			};

			mdio_uio {
				compatible = "marvell,mvmdio-uio";
				mii-bus = <0x45>;
				status = "disabled";
			};

			xmdio_uio {
				compatible = "marvell,mvmdio-uio";
				mii-bus = <0x46>;
				status = "disabled";
			};

			interrupt-controller@1e0000 {
				compatible = "marvell,cp110-icu";
				reg = <0x1e0000 0x440>;
				#address-cells = <0x01>;
				#size-cells = <0x01>;

				interrupt-controller@10 {
					compatible = "marvell,cp110-icu-nsr";
					reg = <0x10 0x20>;
					#interrupt-cells = <0x02>;
					interrupt-controller;
					msi-parent = <0x2a>;
					phandle = <0x3f>;
				};

				interrupt-controller@50 {
					compatible = "marvell,cp110-icu-sei";
					reg = <0x50 0x10>;
					#interrupt-cells = <0x02>;
					interrupt-controller;
					msi-parent = <0x0b>;
					phandle = <0x48>;
				};
			};

			cm3@220000 {
				compatible = "mmio-sram";
				reg = <0x220000 0x800>;
				#address-cells = <0x01>;
				#size-cells = <0x01>;
				ranges = <0x00 0x220000 0x800>;
				phandle = <0x42>;
			};

			rtc@284000 {
				compatible = "marvell,armada-8k-rtc";
				reg = <0x284000 0x20 0x284080 0x24>;
				reg-names = "rtc\0rtc-soc";
				interrupts = <0x4d 0x04>;
				status = "disabled";
			};

			system-controller@440000 {
				compatible = "syscon\0simple-mfd";
				reg = <0x440000 0x2000>;
				phandle = <0x41>;

				clock {
					compatible = "marvell,cp110-clock";
					#clock-cells = <0x02>;
					phandle = <0x40>;
				};

				gpio@100 {
					compatible = "marvell,armada-8k-gpio";
					offset = <0x100>;
					ngpios = <0x20>;
					gpio-controller;
					#gpio-cells = <0x02>;
					gpio-ranges = <0x47 0x00 0x00 0x20>;
					interrupt-controller;
					interrupts = <0x56 0x04 0x55 0x04 0x54 0x04 0x53 0x04>;
					#interrupt-cells = <0x02>;
					status = "okay";
					phandle = <0x3b>;
				};

				gpio@140 {
					compatible = "marvell,armada-8k-gpio";
					offset = <0x140>;
					ngpios = <0x1f>;
					gpio-controller;
					#gpio-cells = <0x02>;
					gpio-ranges = <0x47 0x00 0x20 0x1f>;
					interrupt-controller;
					interrupts = <0x52 0x04 0x51 0x04 0x50 0x04 0x4f 0x04>;
					#interrupt-cells = <0x02>;
					status = "okay";
				};

				pinctrl {
					compatible = "marvell,cp115-standalone-pinctrl";
					phandle = <0x47>;

					cp1-xhci0-vbus-pins {
						marvell,pins = "mpp3";
						marvell,function = "gpio";
						phandle = <0x3a>;
					};

					sfp-pins {
						marvell,pins = "mpp8\0mpp9\0mpp10\0mpp11";
						marvell,function = "gpio";
						phandle = <0x3e>;
					};

					cp1-pcie-reset-pins {
						marvell,pins = "mpp0";
						marvell,function = "gpio";
					};
				};
			};

			system-controller@400000 {
				compatible = "syscon\0simple-mfd";
				reg = <0x400000 0x1000>;
				#address-cells = <0x01>;
				#size-cells = <0x01>;

				thermal-sensor@70 {
					compatible = "marvell,armada-cp110-thermal";
					reg = <0x70 0x10>;
					interrupts-extended = <0x48 0x74 0x04>;
					#thermal-sensor-cells = <0x01>;
					phandle = <0x1a>;
				};
			};

			usb3@500000 {
				compatible = "marvell,armada-8k-xhci\0generic-xhci";
				reg = <0x500000 0x4000>;
				dma-coherent;
				interrupts = <0x6a 0x04>;
				clock-names = "core\0reg";
				clocks = <0x40 0x01 0x16 0x40 0x01 0x10>;
				status = "okay";
				usb-phy = <0x49>;
				phys = <0x4a 0x00>;
				phy-names = "usb";
			};

			usb3@510000 {
				compatible = "marvell,armada-8k-xhci\0generic-xhci";
				reg = <0x510000 0x4000>;
				dma-coherent;
				interrupts = <0x69 0x04>;
				clock-names = "core\0reg";
				clocks = <0x40 0x01 0x17 0x40 0x01 0x10>;
				status = "okay";
				usb-phy = <0x4b>;
				phys = <0x4c 0x01>;
				phy-names = "usb";
			};

			sata@540000 {
				compatible = "marvell,armada-8k-ahci\0generic-ahci";
				reg = <0x540000 0x30000>;
				dma-coherent;
				interrupts = <0x6b 0x04>;
				clocks = <0x40 0x01 0x0f 0x40 0x01 0x10>;
				#address-cells = <0x01>;
				#size-cells = <0x00>;
				status = "okay";

				sata-port@0 {
					reg = <0x00>;
					status = "okay";
					phys = <0x4d 0x00>;
				};

				sata-port@1 {
					reg = <0x01>;
					status = "okay";
					phys = <0x4e 0x01>;
				};
			};

			xor@6a0000 {
				compatible = "marvell,armada-7k-xor\0marvell,xor-v2";
				reg = <0x6a0000 0x1000 0x6b0000 0x1000>;
				dma-coherent;
				msi-parent = <0x03>;
				clock-names = "core\0reg";
				clocks = <0x40 0x01 0x08 0x40 0x01 0x0e>;
				phandle = <0x4f>;
			};

			xor@6c0000 {
				compatible = "marvell,armada-7k-xor\0marvell,xor-v2";
				reg = <0x6c0000 0x1000 0x6d0000 0x1000>;
				dma-coherent;
				msi-parent = <0x03>;
				clock-names = "core\0reg";
				clocks = <0x40 0x01 0x07 0x40 0x01 0x0e>;
				phandle = <0x50>;
			};

			cp1_uio_xor0 {
				compatible = "marvell,uio-xor-v2";
				xor_access = <0x4f>;
			};

			cp1_uio_xor1 {
				compatible = "marvell,uio-xor-v2";
				xor_access = <0x50>;
			};

			spi@700600 {
				compatible = "marvell,armada-380-spi";
				reg = <0x700600 0x50>;
				#address-cells = <0x01>;
				#size-cells = <0x00>;
				clock-names = "core\0axi";
				clocks = <0x40 0x01 0x15 0x40 0x01 0x11>;
				status = "disabled";
			};

			spi@700680 {
				compatible = "marvell,armada-380-spi";
				reg = <0x700680 0x50>;
				#address-cells = <0x01>;
				#size-cells = <0x00>;
				clock-names = "core\0axi";
				clocks = <0x40 0x01 0x15 0x40 0x01 0x11>;
				status = "disabled";
			};

			i2c@701000 {
				compatible = "marvell,mv78230-i2c";
				reg = <0x701000 0x20>;
				#address-cells = <0x01>;
				#size-cells = <0x00>;
				interrupts = <0x78 0x04>;
				clock-names = "core\0reg";
				clocks = <0x40 0x01 0x15 0x40 0x01 0x11>;
				status = "disabled";
				phandle = <0x3d>;
			};

			i2c@701100 {
				compatible = "marvell,mv78230-i2c";
				reg = <0x701100 0x20>;
				#address-cells = <0x01>;
				#size-cells = <0x00>;
				interrupts = <0x79 0x04>;
				clock-names = "core\0reg";
				clocks = <0x40 0x01 0x15 0x40 0x01 0x11>;
				status = "disabled";
			};

			serial@702000 {
				compatible = "snps,dw-apb-uart";
				reg = <0x702000 0x100>;
				reg-shift = <0x02>;
				interrupts = <0x7a 0x04>;
				reg-io-width = <0x01>;
				clock-names = "baudclk\0apb_pclk";
				clocks = <0x40 0x01 0x15 0x40 0x01 0x11>;
				status = "disabled";
			};

			serial@702100 {
				compatible = "snps,dw-apb-uart";
				reg = <0x702100 0x100>;
				reg-shift = <0x02>;
				interrupts = <0x7b 0x04>;
				reg-io-width = <0x01>;
				clock-names = "baudclk\0apb_pclk";
				clocks = <0x40 0x01 0x15 0x40 0x01 0x11>;
				status = "disabled";
			};

			serial@702200 {
				compatible = "snps,dw-apb-uart";
				reg = <0x702200 0x100>;
				reg-shift = <0x02>;
				interrupts = <0x7c 0x04>;
				reg-io-width = <0x01>;
				clock-names = "baudclk\0apb_pclk";
				clocks = <0x40 0x01 0x15 0x40 0x01 0x11>;
				status = "disabled";
			};

			serial@702300 {
				compatible = "snps,dw-apb-uart";
				reg = <0x702300 0x100>;
				reg-shift = <0x02>;
				interrupts = <0x7d 0x04>;
				reg-io-width = <0x01>;
				clock-names = "baudclk\0apb_pclk";
				clocks = <0x40 0x01 0x15 0x40 0x01 0x11>;
				status = "disabled";
			};

			nand@720000 {
				compatible = "marvell,armada-8k-nand-controller\0marvell,armada370-nand-controller";
				reg = <0x720000 0x54>;
				#address-cells = <0x01>;
				#size-cells = <0x00>;
				interrupts = <0x73 0x04>;
				clock-names = "core\0reg";
				clocks = <0x40 0x01 0x02 0x40 0x01 0x11>;
				marvell,system-controller = <0x41>;
				status = "disabled";
			};

			trng@760000 {
				compatible = "marvell,armada-8k-rng\0inside-secure,safexcel-eip76";
				reg = <0x760000 0x7d>;
				interrupts = <0x5f 0x04>;
				clock-names = "core\0reg";
				clocks = <0x40 0x01 0x19 0x40 0x01 0x11>;
				status = "okay";
			};

			sdhci@780000 {
				compatible = "marvell,armada-cp110-sdhci";
				reg = <0x780000 0x300>;
				interrupts = <0x1b 0x04>;
				clock-names = "core\0axi";
				clocks = <0x40 0x01 0x04 0x40 0x01 0x12>;
				dma-coherent;
				status = "disabled";
			};

			crypto@800000 {
				compatible = "inside-secure,safexcel-eip197b";
				reg = <0x800000 0x200000>;
				interrupts = <0x57 0x04 0x58 0x04 0x59 0x04 0x5a 0x04 0x5b 0x04 0x5c 0x04>;
				interrupt-names = "mem\0ring0\0ring1\0ring2\0ring3\0eip";
				clock-names = "core\0reg";
				clocks = <0x40 0x01 0x1a 0x40 0x01 0x11>;
				dma-coherent;
				status = "okay";
				phandle = <0x51>;
			};

			uio_sam@800000 {
				compatible = "marvell,uio-sam";
				eip_access = <0x51>;
			};
		};

		pcie@f4600000 {
			compatible = "marvell,armada8k-pcie\0snps,dw-pcie";
			reg = <0x00 0xf4600000 0x00 0x10000 0x00 0xe2f00000 0x00 0x80000>;
			reg-names = "ctrl\0config";
			#address-cells = <0x03>;
			#size-cells = <0x02>;
			#interrupt-cells = <0x01>;
			device_type = "pci";
			dma-coherent;
			msi-parent = <0x03>;
			bus-range = <0x00 0xff>;
			ranges = <0x82000000 0x00 0xe2000000 0x00 0xe2000000 0x00 0xf00000>;
			interrupt-map-mask = <0x00 0x00 0x00 0x00>;
			interrupt-map = <0x00 0x00 0x00 0x00 0x3f 0x16 0x04>;
			interrupts = <0x16 0x04>;
			num-lanes = <0x01>;
			clock-names = "core\0reg";
			clocks = <0x40 0x01 0x0d 0x40 0x01 0x0e>;
			status = "disabled";
		};

		pcie@f4620000 {
			compatible = "marvell,armada8k-pcie\0snps,dw-pcie";
			reg = <0x00 0xf4620000 0x00 0x10000 0x00 0xe3f00000 0x00 0x80000>;
			reg-names = "ctrl\0config";
			#address-cells = <0x03>;
			#size-cells = <0x02>;
			#interrupt-cells = <0x01>;
			device_type = "pci";
			dma-coherent;
			msi-parent = <0x03>;
			bus-range = <0x00 0xff>;
			ranges = <0x82000000 0x00 0xe3000000 0x00 0xe3000000 0x00 0xf00000>;
			interrupt-map-mask = <0x00 0x00 0x00 0x00>;
			interrupt-map = <0x00 0x00 0x00 0x00 0x3f 0x18 0x04>;
			interrupts = <0x18 0x04>;
			num-lanes = <0x01>;
			clock-names = "core\0reg";
			clocks = <0x40 0x01 0x0b 0x40 0x01 0x0e>;
			status = "disabled";
		};

		pcie@f4640000 {
			compatible = "marvell,armada8k-pcie\0snps,dw-pcie";
			reg = <0x00 0xf4640000 0x00 0x10000 0x00 0xe4f00000 0x00 0x80000>;
			reg-names = "ctrl\0config";
			#address-cells = <0x03>;
			#size-cells = <0x02>;
			#interrupt-cells = <0x01>;
			device_type = "pci";
			dma-coherent;
			msi-parent = <0x03>;
			bus-range = <0x00 0xff>;
			ranges = <0x82000000 0x00 0xe4000000 0x00 0xe4000000 0x00 0xf00000>;
			interrupt-map-mask = <0x00 0x00 0x00 0x00>;
			interrupt-map = <0x00 0x00 0x00 0x00 0x3f 0x17 0x04>;
			interrupts = <0x17 0x04>;
			num-lanes = <0x01>;
			clock-names = "core\0reg";
			clocks = <0x40 0x01 0x0c 0x40 0x01 0x0e>;
			status = "okay";
			num-viewport = <0x08>;
			phys = <0x52 0x02>;
		};
	};
};

&cp0_uart0 {
    status = "okay";
    mcu {
        compatible = "qnap,ts435xeu-mcu";

        pwm: pwm-0 {
            #cooling-cells = <2>;
            cooling-levels = <0 64 89 128 166 204 221 238>;
        };
    };
};

&i2c0 {
    mcu@18 {
        compatible = "qnap,ts435xeu-mcu";
	status = "okay";
	reg = <0x18>;

	sata-drives = <0 1 2 3>;
	m2-drives = <4 5>;
    };
};
